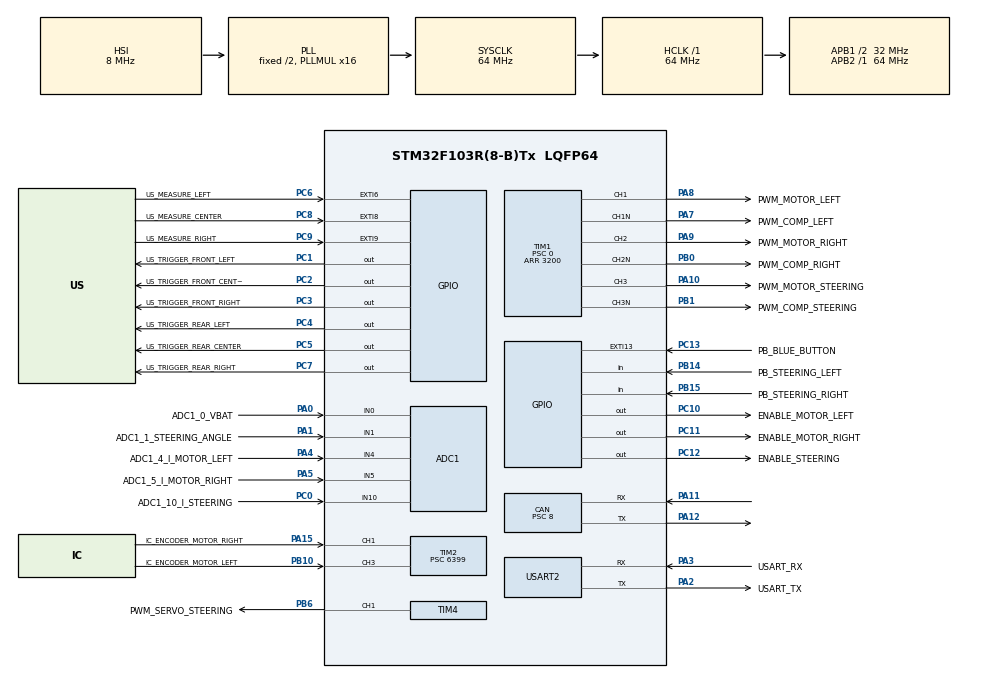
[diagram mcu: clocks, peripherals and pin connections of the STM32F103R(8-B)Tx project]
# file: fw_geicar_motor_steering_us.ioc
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ADC1.Channel-74\#ChannelRegularConversion=ADC_CHANNEL_0
ADC1.Channel-75\#ChannelRegularConversion=ADC_CHANNEL_1
ADC1.Channel-76\#ChannelRegularConversion=ADC_CHANNEL_4
ADC1.Channel-77\#ChannelRegularConversion=ADC_CHANNEL_5
ADC1.Channel-78\#ChannelRegularConversion=ADC_CHANNEL_10
ADC1.ContinuousConvMode=ENABLE
ADC1.DataAlign=ADC_DATAALIGN_RIGHT
ADC1.DiscontinuousConvMode=DISABLE
ADC1.EnableAnalogWatchDog=false
ADC1.EnableRegularConversion=ENABLE
ADC1.ExternalTrigConv=ADC_SOFTWARE_START
ADC1.InjNumberOfConversion=0
ADC1.NbrOfConversion=5
ADC1.NbrOfConversionFlag=1
ADC1.Rank-74\#ChannelRegularConversion=1
ADC1.Rank-75\#ChannelRegularConversion=2
ADC1.Rank-76\#ChannelRegularConversion=3
ADC1.Rank-77\#ChannelRegularConversion=4
ADC1.Rank-78\#ChannelRegularConversion=5
ADC1.SamplingTime-74\#ChannelRegularConversion=ADC_SAMPLETIME_55CYCLES_5
ADC1.SamplingTime-75\#ChannelRegularConversion=ADC_SAMPLETIME_55CYCLES_5
ADC1.SamplingTime-76\#ChannelRegularConversion=ADC_SAMPLETIME_55CYCLES_5
ADC1.SamplingTime-77\#ChannelRegularConversion=ADC_SAMPLETIME_55CYCLES_5
ADC1.SamplingTime-78\#ChannelRegularConversion=ADC_SAMPLETIME_55CYCLES_5
ADC1.ScanConvMode=ADC_SCAN_ENABLE
ADC1.master=1
CAN.BS1=CAN_BS1_7TQ
CAN.BS2=CAN_BS2_2TQ
CAN.CalculateBaudRate=400000
CAN.CalculateTimeBit=2500
CAN.CalculateTimeQuantum=250.0
CAN.Prescaler=8
Dma.ADC1.0.Direction=DMA_PERIPH_TO_MEMORY
Dma.ADC1.0.Instance=DMA1_Channel1
Dma.ADC1.0.MemDataAlignment=DMA_MDATAALIGN_HALFWORD
Dma.ADC1.0.MemInc=DMA_MINC_ENABLE
Dma.ADC1.0.Mode=DMA_CIRCULAR
Dma.ADC1.0.PeriphDataAlignment=DMA_PDATAALIGN_HALFWORD
Dma.ADC1.0.PeriphInc=DMA_PINC_DISABLE
Dma.ADC1.0.Priority=DMA_PRIORITY_LOW
Dma.Request0=ADC1
Mcu.Family=STM32F1
Mcu.Name=STM32F103R(8-B)Tx
Mcu.Package=LQFP64
NVIC.DMA1_Channel1_IRQn=true\:14\:0\:true\:false\:true\:true\:true\:true
NVIC.EXTI15_10_IRQn=true\:12\:0\:true\:false\:true\:true\:true\:true
NVIC.EXTI9_5_IRQn=true\:4\:0\:true\:false\:true\:true\:true\:true
NVIC.PriorityGroup=NVIC_PRIORITYGROUP_4
NVIC.TIM2_IRQn=true\:6\:0\:true\:false\:true\:true\:true\:true
NVIC.TIM3_IRQn=true\:8\:0\:true\:false\:true\:true\:true\:true
NVIC.USB_LP_CAN1_RX0_IRQn=true\:1\:0\:true\:false\:true\:true\:true\:true
PA0-WKUP.GPIO_Label=ADC1_0_VBAT
PA0-WKUP.Signal=ADCx_IN0
PA1.GPIO_Label=ADC1_1_STEERING_ANGLE
PA1.Signal=ADCx_IN1
PA10.GPIO_Label=PWM_MOTOR_STEERING
PA10.Signal=S_TIM1_CH3
PA11.Mode=CAN_Activate
PA11.Signal=CAN_RX
PA12.Mode=CAN_Activate
PA12.Signal=CAN_TX
PA13.GPIO_Label=TMS
PA13.Mode=Trace_Asynchronous_SW
PA13.Signal=SYS_JTMS-SWDIO
PA14.GPIO_Label=TCK
PA14.Mode=Trace_Asynchronous_SW
PA14.Signal=SYS_JTCK-SWCLK
PA15.GPIO_Label=IC_ENCODER_MOTOR_RIGHT
PA15.Signal=S_TIM2_CH1_ETR
PA2.GPIO_Label=USART_TX
PA2.GPIO_Mode=GPIO_MODE_AF_PP
PA2.GPIO_PuPd=GPIO_NOPULL
PA2.GPIO_Speed=GPIO_SPEED_FREQ_LOW
PA2.Mode=Asynchronous
PA2.Signal=USART2_TX
PA3.GPIO_Label=USART_RX
PA3.GPIO_Mode=GPIO_MODE_AF_PP
PA3.GPIO_PuPd=GPIO_NOPULL
PA3.GPIO_Speed=GPIO_SPEED_FREQ_LOW
PA3.Mode=Asynchronous
PA3.Signal=USART2_RX
PA4.GPIO_Label=ADC1_4_I_MOTOR_LEFT
PA4.Signal=ADCx_IN4
PA5.GPIO_Label=ADC1_5_I_MOTOR_RIGHT
PA5.Signal=ADCx_IN5
PA7.GPIO_Label=PWM_COMP_LEFT
PA7.Mode=PWM Generation1 CH1 CH1N
PA7.Signal=TIM1_CH1N
PA8.GPIO_Label=PWM_MOTOR_LEFT
PA8.Signal=S_TIM1_CH1
PA9.GPIO_Label=PWM_MOTOR_RIGHT
PA9.Signal=S_TIM1_CH2
PB0.GPIO_Label=PWM_COMP_RIGHT
PB0.Mode=PWM Generation2 CH2 CH2N
PB0.Signal=TIM1_CH2N
PB1.GPIO_Label=PWM_COMP_STEERING
PB1.Mode=PWM Generation3 CH3 CH3N
PB1.Signal=TIM1_CH3N
PB10.GPIO_Label=IC_ENCODER_MOTOR_LEFT
PB10.Signal=S_TIM2_CH3
PB14.GPIO_Label=PB_STEERING_LEFT
PB14.Signal=GPIO_Input
PB15.GPIO_Label=PB_STEERING_RIGHT
PB15.Signal=GPIO_Input
PB3.Mode=Trace_Asynchronous_SW
PB3.Signal=SYS_JTDO-TRACESWO
PB6.GPIO_Label=PWM_SERVO_STEERING
PB6.Signal=S_TIM4_CH1
PC0.GPIO_Label=ADC1_10_I_STEERING
PC0.Signal=ADCx_IN10
PC1.GPIO_Label=US_TRIGGER_FRONT_LEFT
PC1.Signal=GPIO_Output
PC10.GPIO_Label=ENABLE_MOTOR_LEFT
PC10.Signal=GPIO_Output
PC11.GPIO_Label=ENABLE_MOTOR_RIGHT
PC11.Signal=GPIO_Output
PC12.GPIO_Label=ENABLE_STEERING
PC12.Signal=GPIO_Output
PC13-TAMPER-RTC.GPIO_Label=PB_BLUE_BUTTON
PC13-TAMPER-RTC.GPIO_PuPd=GPIO_NOPULL
PC13-TAMPER-RTC.Signal=GPXTI13
PC2.GPIO_Label=US_TRIGGER_FRONT_CENTER
PC2.Signal=GPIO_Output
PC3.GPIO_Label=US_TRIGGER_FRONT_RIGHT
PC3.Signal=GPIO_Output
PC4.GPIO_Label=US_TRIGGER_REAR_LEFT
PC4.Signal=GPIO_Output
PC5.GPIO_Label=US_TRIGGER_REAR_CENTER
PC5.Signal=GPIO_Output
PC6.GPIO_Label=US_MEASURE_LEFT
PC6.GPIO_ModeDefaultEXTI=GPIO_MODE_IT_RISING_FALLING
PC6.Signal=GPXTI6
PC7.GPIO_Label=US_TRIGGER_REAR_RIGHT
PC7.Signal=GPIO_Output
PC8.GPIO_Label=US_MEASURE_CENTER
PC8.GPIO_ModeDefaultEXTI=GPIO_MODE_IT_RISING_FALLING
PC8.Signal=GPXTI8
PC9.GPIO_Label=US_MEASURE_RIGHT
PC9.GPIO_ModeDefaultEXTI=GPIO_MODE_IT_RISING_FALLING
PC9.Signal=GPXTI9
ProjectManager.HeapSize=0x200
ProjectManager.StackSize=0x400
ProjectManager.TargetToolchain=STM32CubeIDE
RCC.ADCPresc=RCC_ADCPCLK2_DIV8
RCC.AHBFreq_Value=64000000
RCC.APB1CLKDivider=RCC_HCLK_DIV2
RCC.APB1Freq_Value=32000000
RCC.APB1TimFreq_Value=64000000
RCC.APB2Freq_Value=64000000
RCC.APB2TimFreq_Value=64000000
RCC.HCLKFreq_Value=64000000
RCC.PLLMUL=RCC_PLL_MUL16
RCC.RTCClockSelection=RCC_RTCCLKSOURCE_LSE
RCC.SYSCLKFreq_VALUE=64000000
RCC.SYSCLKSource=RCC_SYSCLKSOURCE_PLLCLK
RCC.USBFreq_Value=64000000
SH.ADCx_IN0.0=ADC1_IN0,IN0
SH.ADCx_IN1.0=ADC1_IN1,IN1
SH.ADCx_IN10.0=ADC1_IN10,IN10
SH.ADCx_IN4.0=ADC1_IN4,IN4
SH.ADCx_IN5.0=ADC1_IN5,IN5
SH.S_TIM1_CH1.0=TIM1_CH1,PWM Generation1 CH1 CH1N
SH.S_TIM1_CH2.0=TIM1_CH2,PWM Generation2 CH2 CH2N
SH.S_TIM1_CH3.0=TIM1_CH3,PWM Generation3 CH3 CH3N
SH.S_TIM2_CH1_ETR.0=TIM2_CH1,Input_Capture1_from_TI1
SH.S_TIM2_CH3.0=TIM2_CH3,Input_Capture3_from_TI3
SH.S_TIM4_CH1.0=TIM4_CH1,PWM Generation1 CH1
TIM1.Channel-PWM\ Generation1\ CH1\ CH1N=TIM_CHANNEL_1
TIM1.Channel-PWM\ Generation2\ CH2\ CH2N=TIM_CHANNEL_2
TIM1.Channel-PWM\ Generation3\ CH3\ CH3N=TIM_CHANNEL_3
TIM1.OCNPolarity_1=TIM_OCNPOLARITY_HIGH
TIM1.Period=3200
TIM1.Prescaler=0
TIM1.Pulse-PWM\ Generation1\ CH1\ CH1N=320
TIM1.Pulse-PWM\ Generation2\ CH2\ CH2N=1600
TIM1.Pulse-PWM\ Generation3\ CH3\ CH3N=1600
TIM1.RepetitionCounter=0
TIM2.Channel-Input_Capture1_from_TI1=TIM_CHANNEL_1
TIM2.Channel-Input_Capture3_from_TI3=TIM_CHANNEL_3
TIM2.Period=65535
TIM2.Prescaler=6399
TIM3.Period=65535
TIM3.Prescaler=63
TIM4.AutoReloadPreload=TIM_AUTORELOAD_PRELOAD_ENABLE
TIM4.Channel-PWM\ Generation1\ CH1=TIM_CHANNEL_1
TIM4.Period=63999
TIM4.Prescaler=9
USART2.VirtualMode=VM_ASYNC
VP_TIM2_VS_ClockSourceINT.Mode=Internal
VP_TIM3_VS_ClockSourceINT.Mode=Internal
VP_TIM4_VS_ClockSourceINT.Mode=Internal
board=NUCLEO-F103RB

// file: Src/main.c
/* USER CODE BEGIN Header */
/**
  ******************************************************************************
  * @file           : main.c
  * @brief          : Main program body
  ******************************************************************************
  * @attention
  *
  * Copyright (c) 2025 STMicroelectronics.
  * All rights reserved.
  *
  * This software is licensed under terms that can be found in the LICENSE file
  * in the root directory of this software component.
  * If no LICENSE file comes with this software, it is provided AS-IS.
  *
  ******************************************************************************
  */
/* USER CODE END Header */
#include "main.h"
#include "adc.h"
#include "can.h"
#include "dma.h"
#include "tim.h"
#include "usart.h"
#include "gpio.h"

/* USER CODE BEGIN Includes */
#include "app.h"
#include <stdio.h>

/* USER CODE END Includes */

/* USER CODE BEGIN PV */
/* Private variables ---------------------------------------------------------*/

/* USER CODE END PV */

void SystemClock_Config(void);
/* USER CODE BEGIN PFP */
/* Private function prototypes -----------------------------------------------*/

/* USER CODE END PFP */

int main(void)
{

  /* MCU Configuration--------------------------------------------------------*/

  /* Reset of all peripherals, Initializes the Flash interface and the Systick. */
  HAL_Init();

  /* Configure the system clock */
  SystemClock_Config();

  /* Initialize all configured peripherals */
  MX_GPIO_Init();
  MX_DMA_Init();
  MX_USART2_UART_Init();
  MX_TIM1_Init();
  MX_TIM2_Init();
  MX_TIM4_Init();
  MX_ADC1_Init();
  MX_CAN_Init();
  MX_TIM3_Init();
  /* USER CODE BEGIN 2 */

  APP_Init();
  APP_Run();    /* Never returns */
  /* USER CODE END 2 */

  /* Infinite loop */
  /* USER CODE BEGIN WHILE */
  for (;;);

    /* USER CODE END WHILE */

}

void SystemClock_Config(void)
{
  RCC_OscInitTypeDef RCC_OscInitStruct = {0};
  RCC_ClkInitTypeDef RCC_ClkInitStruct = {0};
  RCC_PeriphCLKInitTypeDef PeriphClkInit = {0};

  /** Initializes the RCC Oscillators according to the specified parameters
  * in the RCC_OscInitTypeDef structure.
  */
  RCC_OscInitStruct.OscillatorType = RCC_OSCILLATORTYPE_HSI;
  RCC_OscInitStruct.HSIState = RCC_HSI_ON;
  RCC_OscInitStruct.HSICalibrationValue = RCC_HSICALIBRATION_DEFAULT;
  RCC_OscInitStruct.PLL.PLLState = RCC_PLL_ON;
  RCC_OscInitStruct.PLL.PLLSource = RCC_PLLSOURCE_HSI_DIV2;
  RCC_OscInitStruct.PLL.PLLMUL = RCC_PLL_MUL16;
  if (HAL_RCC_OscConfig(&RCC_OscInitStruct) != HAL_OK)
  {
    Error_Handler();
  }

  /** Initializes the CPU, AHB and APB buses clocks
  */
  RCC_ClkInitStruct.ClockType = RCC_CLOCKTYPE_HCLK|RCC_CLOCKTYPE_SYSCLK
                              |RCC_CLOCKTYPE_PCLK1|RCC_CLOCKTYPE_PCLK2;
  RCC_ClkInitStruct.SYSCLKSource = RCC_SYSCLKSOURCE_PLLCLK;
  RCC_ClkInitStruct.AHBCLKDivider = RCC_SYSCLK_DIV1;
  RCC_ClkInitStruct.APB1CLKDivider = RCC_HCLK_DIV2;
  RCC_ClkInitStruct.APB2CLKDivider = RCC_HCLK_DIV1;

  if (HAL_RCC_ClockConfig(&RCC_ClkInitStruct, FLASH_LATENCY_2) != HAL_OK)
  {
    Error_Handler();
  }
  PeriphClkInit.PeriphClockSelection = RCC_PERIPHCLK_ADC;
  PeriphClkInit.AdcClockSelection = RCC_ADCPCLK2_DIV8;
  if (HAL_RCCEx_PeriphCLKConfig(&PeriphClkInit) != HAL_OK)
  {
    Error_Handler();
  }
}

void Error_Handler(void)
{
  /* USER CODE BEGIN Error_Handler_Debug */
    /* User can add his own implementation to report the HAL error return state */
	printf("\r\nERROR - SYSTEM HALTED\r\n");
    for (;;);
  /* USER CODE END Error_Handler_Debug */
}

#ifdef  USE_FULL_ASSERT
/**
  * @brief  Reports the name of the source file and the source line number
  *         where the assert_param error has occurred.
  * @param  file: pointer to the source file name
  * @param  line: assert_param error line source number
  * @retval None
  */
void assert_failed(uint8_t *file, uint32_t line)
{
  /* USER CODE BEGIN 6 */
  printf("Assert failed in file %s on line %ld\r\n", file, line);
  /* USER CODE END 6 */
}
#endif /* USE_FULL_ASSERT */
